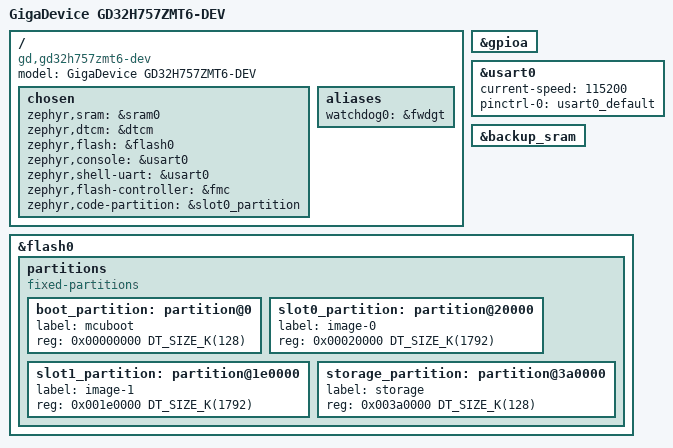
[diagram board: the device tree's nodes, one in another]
/*
 * Copyright (c) 2026 GigaDevice Semiconductor Inc.
 *
 * SPDX-License-Identifier: Apache-2.0
 */

/dts-v1/;

#include <gd/gd32h7xx/gd32h757zm.dtsi>
#include "gd32h757zmt6_dev-pinctrl.dtsi"

/ {
	model = "GigaDevice GD32H757ZMT6-DEV";
	compatible = "gd,gd32h757zmt6-dev";

	chosen {
		zephyr,sram = &sram0;
		zephyr,dtcm = &dtcm;
		zephyr,flash = &flash0;
		zephyr,console = &usart0;
		zephyr,shell-uart = &usart0;
		zephyr,flash-controller = &fmc;
		zephyr,code-partition = &slot0_partition;
	};

	aliases {
		watchdog0 = &fwdgt;
	};
};

&gpioa {
	status = "okay";
};

&usart0 {
	status = "okay";
	current-speed = <115200>;
	pinctrl-0 = <&usart0_default>;
	pinctrl-names = "default";
};

&backup_sram {
	status = "okay";
};

/*
 * Flash partition table (3840 KB at 0x08000000), MCUboot-ready:
 *   mcuboot 128 KB, image-0 (slot0) 1792 KB, image-1 (slot1) 1792 KB,
 *   storage 128 KB (settings/NVS). Without CONFIG_BOOTLOADER_MCUBOOT the app
 *   still links at the flash base; with it (sysbuild), at slot0.
 */
&flash0 {
	partitions {
		compatible = "fixed-partitions";
		#address-cells = <1>;
		#size-cells = <1>;

		boot_partition: partition@0 {
			label = "mcuboot";
			reg = <0x00000000 DT_SIZE_K(128)>;
		};

		slot0_partition: partition@20000 {
			label = "image-0";
			reg = <0x00020000 DT_SIZE_K(1792)>;
		};

		slot1_partition: partition@1e0000 {
			label = "image-1";
			reg = <0x001e0000 DT_SIZE_K(1792)>;
		};

		storage_partition: partition@3a0000 {
			label = "storage";
			reg = <0x003a0000 DT_SIZE_K(128)>;
		};
	};
};
